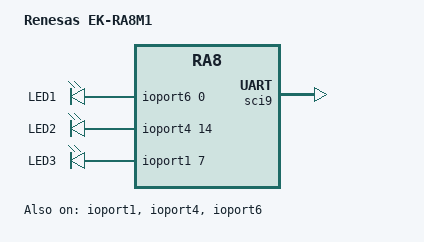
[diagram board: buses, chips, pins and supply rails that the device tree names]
/*
 * Copyright (c) 2024 Renesas Electronics Corporation
 * SPDX-License-Identifier: Apache-2.0
 */

/dts-v1/;

#include <renesas/ra/ra8/r7fa8m1ahecbd.dtsi>
#include <dt-bindings/gpio/gpio.h>

#include "ek_ra8m1-pinctrl.dtsi"

/ {
	model = "Renesas EK-RA8M1";
	compatible = "renesas,ra8m1", "renesas,ra8";

	chosen {
		zephyr,sram = &sram0;
		zephyr,flash = &flash0;
		zephyr,console = &uart9;
		zephyr,shell-uart = &uart9;
	};

	leds {
		compatible = "gpio-leds";
		led1: led1 {
			gpios = <&ioport6 0 GPIO_ACTIVE_HIGH>;
			label = "LED1";
		};
		led2: led2 {
			gpios = <&ioport4 14 GPIO_ACTIVE_HIGH>;
			label = "LED2";
		};
		led3: led3 {
			gpios = <&ioport1 7 GPIO_ACTIVE_HIGH>;
			label = "LED3";
		};
	};

	aliases {
		led0 = &led1;
	};
};

&clock {
	sciclk-source = <RA_CLOCK_SOURCE_PLL1P>;
	sciclk-div = <RA_SCI_CLOCK_DIV_4>;
};

&ioport1 {
	status = "okay";
};

&ioport4 {
	status = "okay";
};

&ioport6 {
	status = "okay";
};

&sci9 {
	pinctrl-0 = <&sci9_default>;
	pinctrl-names = "default";
	status = "okay";
	uart9: uart {
		current-speed = <115200>;
		status = "okay";
	};
};
